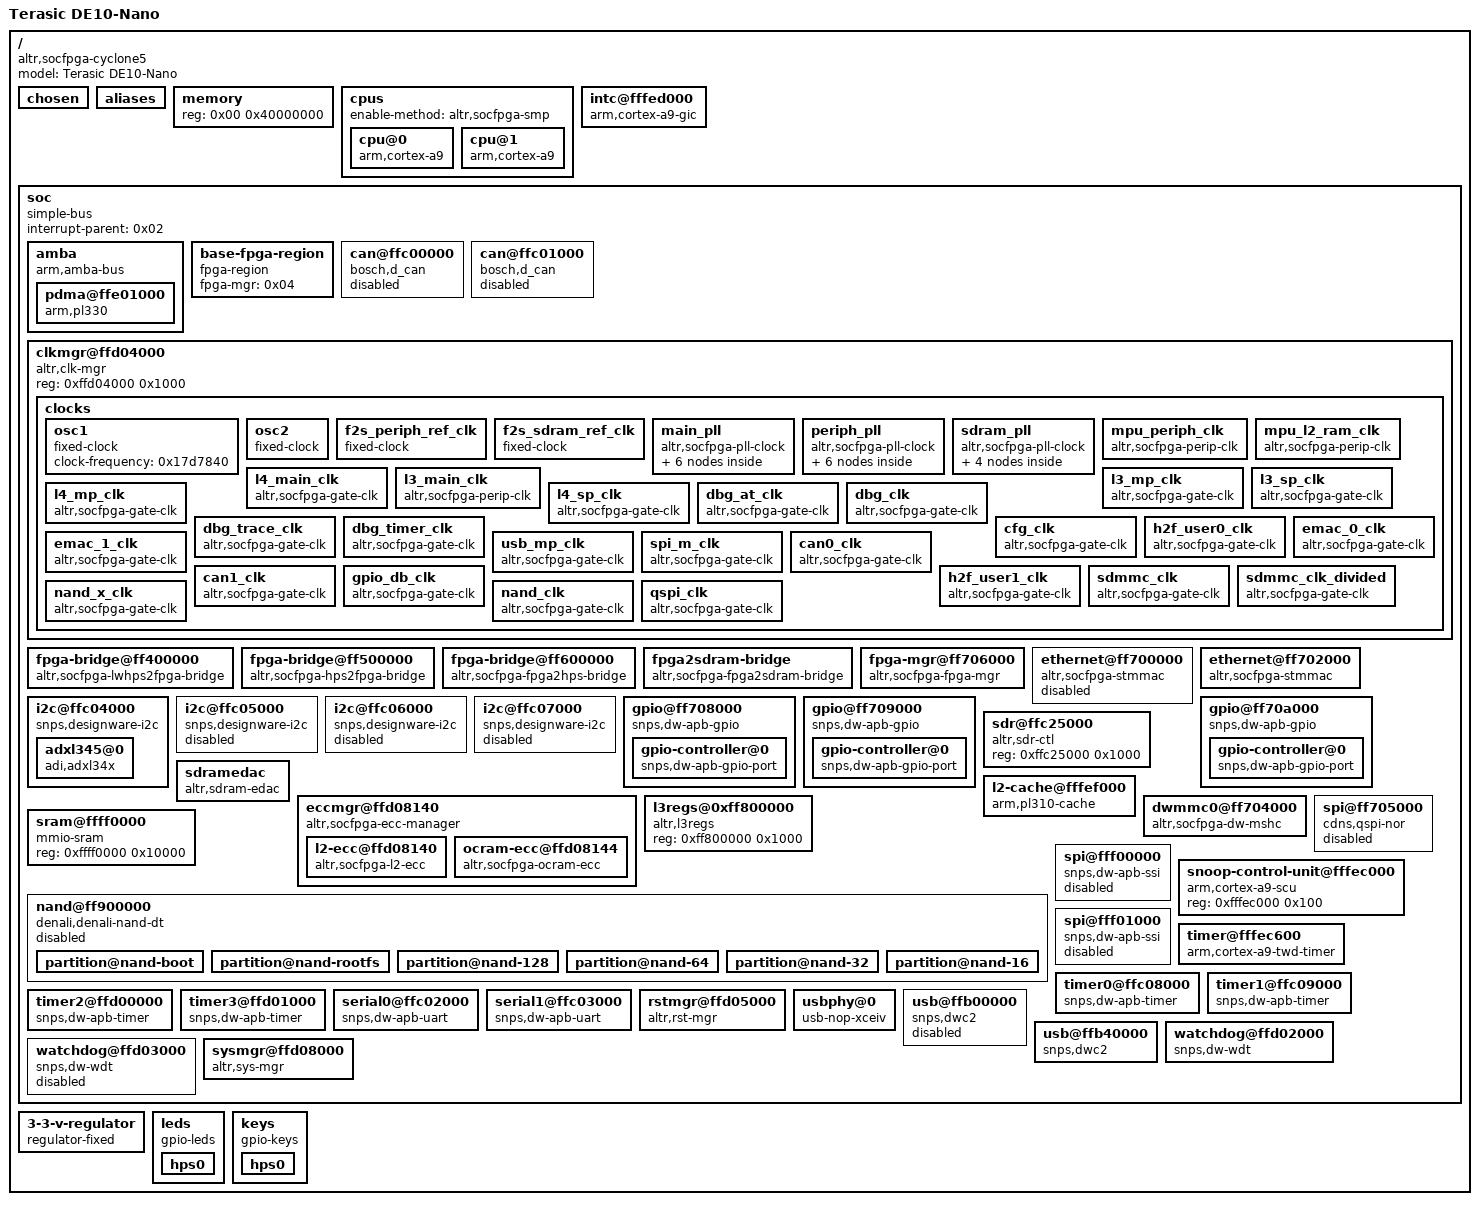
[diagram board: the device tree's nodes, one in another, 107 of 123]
/dts-v1/;

/memreserve/	0x0000000000000000 0x0000000000001000;
/ {
	#address-cells = <0x01>;
	#size-cells = <0x01>;
	model = "Terasic DE10-Nano";
	compatible = "altr,socfpga-cyclone5\0altr,socfpga";

	chosen {
		bootargs = "earlyprintk";
		stdout-path = "serial0:115200n8";
	};

	aliases {
		ethernet0 = "/soc/ethernet@ff702000";
		ethernet1 = "/soc/ethernet@ff702000";
		serial0 = "/soc/serial0@ffc02000";
		serial1 = "/soc/serial1@ffc03000";
		timer0 = "/soc/timer0@ffc08000";
		timer1 = "/soc/timer1@ffc09000";
		timer2 = "/soc/timer2@ffd00000";
		timer3 = "/soc/timer3@ffd01000";
	};

	memory {
		device_type = "memory";
		reg = <0x00 0x40000000>;
	};

	cpus {
		#address-cells = <0x01>;
		#size-cells = <0x00>;
		enable-method = "altr,socfpga-smp";

		cpu@0 {
			compatible = "arm,cortex-a9";
			device_type = "cpu";
			reg = <0x00>;
			next-level-cache = <0x01>;
		};

		cpu@1 {
			compatible = "arm,cortex-a9";
			device_type = "cpu";
			reg = <0x01>;
			next-level-cache = <0x01>;
		};
	};

	intc@fffed000 {
		compatible = "arm,cortex-a9-gic";
		#interrupt-cells = <0x03>;
		interrupt-controller;
		reg = <0xfffed000 0x1000 0xfffec100 0x100>;
		linux,phandle = <0x02>;
		phandle = <0x02>;
	};

	soc {
		#address-cells = <0x01>;
		#size-cells = <0x01>;
		compatible = "simple-bus";
		device_type = "soc";
		interrupt-parent = <0x02>;
		ranges;

		amba {
			compatible = "arm,amba-bus";
			#address-cells = <0x01>;
			#size-cells = <0x01>;
			ranges;

			pdma@ffe01000 {
				compatible = "arm,pl330\0arm,primecell";
				reg = <0xffe01000 0x1000>;
				interrupts = <0x00 0x68 0x04 0x00 0x69 0x04 0x00 0x6a 0x04 0x00 0x6b 0x04 0x00 0x6c 0x04 0x00 0x6d 0x04 0x00 0x6e 0x04 0x00 0x6f 0x04>;
				#dma-cells = <0x01>;
				#dma-channels = <0x08>;
				#dma-requests = <0x20>;
				clocks = <0x03>;
				clock-names = "apb_pclk";
				linux,phandle = <0x28>;
				phandle = <0x28>;
			};
		};

		base-fpga-region {
			compatible = "fpga-region";
			fpga-mgr = <0x04>;
			#address-cells = <0x01>;
			#size-cells = <0x01>;
			linux,phandle = <0x2d>;
			phandle = <0x2d>;
		};

		can@ffc00000 {
			compatible = "bosch,d_can";
			reg = <0xffc00000 0x1000>;
			interrupts = <0x00 0x83 0x04 0x00 0x84 0x04 0x00 0x85 0x04 0x00 0x86 0x04>;
			clocks = <0x05>;
			status = "disabled";
			linux,phandle = <0x2e>;
			phandle = <0x2e>;
		};

		can@ffc01000 {
			compatible = "bosch,d_can";
			reg = <0xffc01000 0x1000>;
			interrupts = <0x00 0x87 0x04 0x00 0x88 0x04 0x00 0x89 0x04 0x00 0x8a 0x04>;
			clocks = <0x06>;
			status = "disabled";
			linux,phandle = <0x2f>;
			phandle = <0x2f>;
		};

		clkmgr@ffd04000 {
			compatible = "altr,clk-mgr";
			reg = <0xffd04000 0x1000>;

			clocks {
				#address-cells = <0x01>;
				#size-cells = <0x00>;

				osc1 {
					#clock-cells = <0x00>;
					compatible = "fixed-clock";
					clock-frequency = <0x17d7840>;
					linux,phandle = <0x07>;
					phandle = <0x07>;
				};

				osc2 {
					#clock-cells = <0x00>;
					compatible = "fixed-clock";
					linux,phandle = <0x09>;
					phandle = <0x09>;
				};

				f2s_periph_ref_clk {
					#clock-cells = <0x00>;
					compatible = "fixed-clock";
					linux,phandle = <0x0a>;
					phandle = <0x0a>;
				};

				f2s_sdram_ref_clk {
					#clock-cells = <0x00>;
					compatible = "fixed-clock";
					linux,phandle = <0x0c>;
					phandle = <0x0c>;
				};

				main_pll {
					#address-cells = <0x01>;
					#size-cells = <0x00>;
					#clock-cells = <0x00>;
					compatible = "altr,socfpga-pll-clock";
					clocks = <0x07>;
					reg = <0x40>;
					linux,phandle = <0x08>;
					phandle = <0x08>;

					mpuclk {
						#clock-cells = <0x00>;
						compatible = "altr,socfpga-perip-clk";
						clocks = <0x08>;
						div-reg = <0xe0 0x00 0x09>;
						reg = <0x48>;
						linux,phandle = <0x0e>;
						phandle = <0x0e>;
					};

					mainclk {
						#clock-cells = <0x00>;
						compatible = "altr,socfpga-perip-clk";
						clocks = <0x08>;
						div-reg = <0xe4 0x00 0x09>;
						reg = <0x4c>;
						linux,phandle = <0x0f>;
						phandle = <0x0f>;
					};

					dbg_base_clk {
						#clock-cells = <0x00>;
						compatible = "altr,socfpga-perip-clk";
						clocks = <0x08 0x07>;
						div-reg = <0xe8 0x00 0x09>;
						reg = <0x50>;
						linux,phandle = <0x12>;
						phandle = <0x12>;
					};

					main_qspi_clk {
						#clock-cells = <0x00>;
						compatible = "altr,socfpga-perip-clk";
						clocks = <0x08>;
						reg = <0x54>;
						linux,phandle = <0x1b>;
						phandle = <0x1b>;
					};

					main_nand_sdmmc_clk {
						#clock-cells = <0x00>;
						compatible = "altr,socfpga-perip-clk";
						clocks = <0x08>;
						reg = <0x58>;
						linux,phandle = <0x18>;
						phandle = <0x18>;
					};

					cfg_h2f_usr0_clk {
						#clock-cells = <0x00>;
						compatible = "altr,socfpga-perip-clk";
						clocks = <0x08>;
						reg = <0x5c>;
						linux,phandle = <0x14>;
						phandle = <0x14>;
					};
				};

				periph_pll {
					#address-cells = <0x01>;
					#size-cells = <0x00>;
					#clock-cells = <0x00>;
					compatible = "altr,socfpga-pll-clock";
					clocks = <0x07 0x09 0x0a>;
					reg = <0x80>;
					linux,phandle = <0x0b>;
					phandle = <0x0b>;

					emac0_clk {
						#clock-cells = <0x00>;
						compatible = "altr,socfpga-perip-clk";
						clocks = <0x0b>;
						reg = <0x88>;
						linux,phandle = <0x15>;
						phandle = <0x15>;
					};

					emac1_clk {
						#clock-cells = <0x00>;
						compatible = "altr,socfpga-perip-clk";
						clocks = <0x0b>;
						reg = <0x8c>;
						linux,phandle = <0x16>;
						phandle = <0x16>;
					};

					per_qsi_clk {
						#clock-cells = <0x00>;
						compatible = "altr,socfpga-perip-clk";
						clocks = <0x0b>;
						reg = <0x90>;
						linux,phandle = <0x1c>;
						phandle = <0x1c>;
					};

					per_nand_mmc_clk {
						#clock-cells = <0x00>;
						compatible = "altr,socfpga-perip-clk";
						clocks = <0x0b>;
						reg = <0x94>;
						linux,phandle = <0x19>;
						phandle = <0x19>;
					};

					per_base_clk {
						#clock-cells = <0x00>;
						compatible = "altr,socfpga-perip-clk";
						clocks = <0x0b>;
						reg = <0x98>;
						linux,phandle = <0x11>;
						phandle = <0x11>;
					};

					h2f_usr1_clk {
						#clock-cells = <0x00>;
						compatible = "altr,socfpga-perip-clk";
						clocks = <0x0b>;
						reg = <0x9c>;
						linux,phandle = <0x17>;
						phandle = <0x17>;
					};
				};

				sdram_pll {
					#address-cells = <0x01>;
					#size-cells = <0x00>;
					#clock-cells = <0x00>;
					compatible = "altr,socfpga-pll-clock";
					clocks = <0x07 0x09 0x0c>;
					reg = <0xc0>;
					linux,phandle = <0x0d>;
					phandle = <0x0d>;

					ddr_dqs_clk {
						#clock-cells = <0x00>;
						compatible = "altr,socfpga-perip-clk";
						clocks = <0x0d>;
						reg = <0xc8>;
						linux,phandle = <0x30>;
						phandle = <0x30>;
					};

					ddr_2x_dqs_clk {
						#clock-cells = <0x00>;
						compatible = "altr,socfpga-perip-clk";
						clocks = <0x0d>;
						reg = <0xcc>;
						linux,phandle = <0x31>;
						phandle = <0x31>;
					};

					ddr_dq_clk {
						#clock-cells = <0x00>;
						compatible = "altr,socfpga-perip-clk";
						clocks = <0x0d>;
						reg = <0xd0>;
						linux,phandle = <0x32>;
						phandle = <0x32>;
					};

					h2f_usr2_clk {
						#clock-cells = <0x00>;
						compatible = "altr,socfpga-perip-clk";
						clocks = <0x0d>;
						reg = <0xd4>;
						linux,phandle = <0x33>;
						phandle = <0x33>;
					};
				};

				mpu_periph_clk {
					#clock-cells = <0x00>;
					compatible = "altr,socfpga-perip-clk";
					clocks = <0x0e>;
					fixed-divider = <0x04>;
					linux,phandle = <0x29>;
					phandle = <0x29>;
				};

				mpu_l2_ram_clk {
					#clock-cells = <0x00>;
					compatible = "altr,socfpga-perip-clk";
					clocks = <0x0e>;
					fixed-divider = <0x02>;
					linux,phandle = <0x34>;
					phandle = <0x34>;
				};

				l4_main_clk {
					#clock-cells = <0x00>;
					compatible = "altr,socfpga-gate-clk";
					clocks = <0x0f>;
					clk-gate = <0x60 0x00>;
					linux,phandle = <0x03>;
					phandle = <0x03>;
				};

				l3_main_clk {
					#clock-cells = <0x00>;
					compatible = "altr,socfpga-perip-clk";
					clocks = <0x0f>;
					fixed-divider = <0x01>;
					linux,phandle = <0x35>;
					phandle = <0x35>;
				};

				l3_mp_clk {
					#clock-cells = <0x00>;
					compatible = "altr,socfpga-gate-clk";
					clocks = <0x0f>;
					div-reg = <0x64 0x00 0x02>;
					clk-gate = <0x60 0x01>;
					linux,phandle = <0x10>;
					phandle = <0x10>;
				};

				l3_sp_clk {
					#clock-cells = <0x00>;
					compatible = "altr,socfpga-gate-clk";
					clocks = <0x10>;
					div-reg = <0x64 0x02 0x02>;
					linux,phandle = <0x36>;
					phandle = <0x36>;
				};

				l4_mp_clk {
					#clock-cells = <0x00>;
					compatible = "altr,socfpga-gate-clk";
					clocks = <0x0f 0x11>;
					div-reg = <0x64 0x04 0x03>;
					clk-gate = <0x60 0x02>;
					linux,phandle = <0x21>;
					phandle = <0x21>;
				};

				l4_sp_clk {
					#clock-cells = <0x00>;
					compatible = "altr,socfpga-gate-clk";
					clocks = <0x0f 0x11>;
					div-reg = <0x64 0x07 0x03>;
					clk-gate = <0x60 0x03>;
					linux,phandle = <0x1f>;
					phandle = <0x1f>;
				};

				dbg_at_clk {
					#clock-cells = <0x00>;
					compatible = "altr,socfpga-gate-clk";
					clocks = <0x12>;
					div-reg = <0x68 0x00 0x02>;
					clk-gate = <0x60 0x04>;
					linux,phandle = <0x13>;
					phandle = <0x13>;
				};

				dbg_clk {
					#clock-cells = <0x00>;
					compatible = "altr,socfpga-gate-clk";
					clocks = <0x13>;
					div-reg = <0x68 0x02 0x02>;
					clk-gate = <0x60 0x05>;
					linux,phandle = <0x37>;
					phandle = <0x37>;
				};

				dbg_trace_clk {
					#clock-cells = <0x00>;
					compatible = "altr,socfpga-gate-clk";
					clocks = <0x12>;
					div-reg = <0x6c 0x00 0x03>;
					clk-gate = <0x60 0x06>;
					linux,phandle = <0x38>;
					phandle = <0x38>;
				};

				dbg_timer_clk {
					#clock-cells = <0x00>;
					compatible = "altr,socfpga-gate-clk";
					clocks = <0x12>;
					clk-gate = <0x60 0x07>;
					linux,phandle = <0x39>;
					phandle = <0x39>;
				};

				cfg_clk {
					#clock-cells = <0x00>;
					compatible = "altr,socfpga-gate-clk";
					clocks = <0x14>;
					clk-gate = <0x60 0x08>;
					linux,phandle = <0x3a>;
					phandle = <0x3a>;
				};

				h2f_user0_clk {
					#clock-cells = <0x00>;
					compatible = "altr,socfpga-gate-clk";
					clocks = <0x14>;
					clk-gate = <0x60 0x09>;
					linux,phandle = <0x3b>;
					phandle = <0x3b>;
				};

				emac_0_clk {
					#clock-cells = <0x00>;
					compatible = "altr,socfpga-gate-clk";
					clocks = <0x15>;
					clk-gate = <0xa0 0x00>;
					linux,phandle = <0x3c>;
					phandle = <0x3c>;
				};

				emac_1_clk {
					#clock-cells = <0x00>;
					compatible = "altr,socfpga-gate-clk";
					clocks = <0x16>;
					clk-gate = <0xa0 0x01>;
					linux,phandle = <0x3d>;
					phandle = <0x3d>;
				};

				usb_mp_clk {
					#clock-cells = <0x00>;
					compatible = "altr,socfpga-gate-clk";
					clocks = <0x11>;
					clk-gate = <0xa0 0x02>;
					div-reg = <0xa4 0x00 0x03>;
					linux,phandle = <0x2a>;
					phandle = <0x2a>;
				};

				spi_m_clk {
					#clock-cells = <0x00>;
					compatible = "altr,socfpga-gate-clk";
					clocks = <0x11>;
					clk-gate = <0xa0 0x03>;
					div-reg = <0xa4 0x03 0x03>;
					linux,phandle = <0x3e>;
					phandle = <0x3e>;
				};

				can0_clk {
					#clock-cells = <0x00>;
					compatible = "altr,socfpga-gate-clk";
					clocks = <0x11>;
					clk-gate = <0xa0 0x04>;
					div-reg = <0xa4 0x06 0x03>;
					linux,phandle = <0x05>;
					phandle = <0x05>;
				};

				can1_clk {
					#clock-cells = <0x00>;
					compatible = "altr,socfpga-gate-clk";
					clocks = <0x11>;
					clk-gate = <0xa0 0x05>;
					div-reg = <0xa4 0x09 0x03>;
					linux,phandle = <0x06>;
					phandle = <0x06>;
				};

				gpio_db_clk {
					#clock-cells = <0x00>;
					compatible = "altr,socfpga-gate-clk";
					clocks = <0x11>;
					clk-gate = <0xa0 0x06>;
					div-reg = <0xa8 0x00 0x18>;
					linux,phandle = <0x3f>;
					phandle = <0x3f>;
				};

				h2f_user1_clk {
					#clock-cells = <0x00>;
					compatible = "altr,socfpga-gate-clk";
					clocks = <0x17>;
					clk-gate = <0xa0 0x07>;
					linux,phandle = <0x40>;
					phandle = <0x40>;
				};

				sdmmc_clk {
					#clock-cells = <0x00>;
					compatible = "altr,socfpga-gate-clk";
					clocks = <0x0a 0x18 0x19>;
					clk-gate = <0xa0 0x08>;
					clk-phase = <0x00 0x87>;
					linux,phandle = <0x1a>;
					phandle = <0x1a>;
				};

				sdmmc_clk_divided {
					#clock-cells = <0x00>;
					compatible = "altr,socfpga-gate-clk";
					clocks = <0x1a>;
					clk-gate = <0xa0 0x08>;
					fixed-divider = <0x04>;
					linux,phandle = <0x24>;
					phandle = <0x24>;
				};

				nand_x_clk {
					#clock-cells = <0x00>;
					compatible = "altr,socfpga-gate-clk";
					clocks = <0x0a 0x18 0x19>;
					clk-gate = <0xa0 0x09>;
					linux,phandle = <0x41>;
					phandle = <0x41>;
				};

				nand_clk {
					#clock-cells = <0x00>;
					compatible = "altr,socfpga-gate-clk";
					clocks = <0x0a 0x18 0x19>;
					clk-gate = <0xa0 0x0a>;
					fixed-divider = <0x04>;
					linux,phandle = <0x26>;
					phandle = <0x26>;
				};

				qspi_clk {
					#clock-cells = <0x00>;
					compatible = "altr,socfpga-gate-clk";
					clocks = <0x0a 0x1b 0x1c>;
					clk-gate = <0xa0 0x0b>;
					linux,phandle = <0x27>;
					phandle = <0x27>;
				};
			};
		};

		fpga-bridge@ff400000 {
			compatible = "altr,socfpga-lwhps2fpga-bridge";
			reg = <0xff400000 0x100000>;
			resets = <0x1d 0x61>;
			reset-names = "lwhps2fpga";
			clocks = <0x03>;
			linux,phandle = <0x42>;
			phandle = <0x42>;
		};

		fpga-bridge@ff500000 {
			compatible = "altr,socfpga-hps2fpga-bridge";
			reg = <0xff500000 0x10000>;
			resets = <0x1d 0x60>;
			reset-names = "hps2fpga";
			clocks = <0x03>;
			linux,phandle = <0x43>;
			phandle = <0x43>;
		};

		fpga-bridge@ff600000 {
			compatible = "altr,socfpga-fpga2hps-bridge";
			reg = <0xff600000 0x100000>;
			resets = <0x1d 0x62>;
			reset-names = "fpga2hps";
			clocks = <0x03>;
			linux,phandle = <0x44>;
			phandle = <0x44>;
		};

		fpga2sdram-bridge {
			compatible = "altr,socfpga-fpga2sdram-bridge";
			linux,phandle = <0x45>;
			phandle = <0x45>;
		};

		fpga-mgr@ff706000 {
			compatible = "altr,socfpga-fpga-mgr";
			reg = <0xff706000 0x1000 0xffb90000 0x20>;
			interrupts = <0x00 0xaf 0x04>;
			linux,phandle = <0x04>;
			phandle = <0x04>;
		};

		ethernet@ff700000 {
			compatible = "altr,socfpga-stmmac\0snps,dwmac-3.70a\0snps,dwmac";
			altr,sysmgr-syscon = <0x1e 0x60 0x00>;
			reg = <0xff700000 0x2000>;
			interrupts = <0x00 0x73 0x04>;
			interrupt-names = "macirq";
			mac-address = [00 00 00 00 00 00];
			clocks = <0x15>;
			clock-names = "stmmaceth";
			resets = <0x1d 0x20>;
			reset-names = "stmmaceth";
			snps,multicast-filter-bins = <0x100>;
			snps,perfect-filter-entries = <0x80>;
			tx-fifo-depth = <0x1000>;
			rx-fifo-depth = <0x1000>;
			status = "disabled";
			linux,phandle = <0x46>;
			phandle = <0x46>;
		};

		ethernet@ff702000 {
			compatible = "altr,socfpga-stmmac\0snps,dwmac-3.70a\0snps,dwmac";
			altr,sysmgr-syscon = <0x1e 0x60 0x02>;
			reg = <0xff702000 0x2000>;
			interrupts = <0x00 0x78 0x04>;
			interrupt-names = "macirq";
			mac-address = [00 00 00 00 00 00];
			clocks = <0x16>;
			clock-names = "stmmaceth";
			resets = <0x1d 0x21>;
			reset-names = "stmmaceth";
			snps,multicast-filter-bins = <0x100>;
			snps,perfect-filter-entries = <0x80>;
			tx-fifo-depth = <0x1000>;
			rx-fifo-depth = <0x1000>;
			status = "okay";
			phy-mode = "rgmii";
			phy-addr = <0xffffffff>;
			txd0-skew-ps = <0x00>;
			txd1-skew-ps = <0x00>;
			txd2-skew-ps = <0x00>;
			txd3-skew-ps = <0x00>;
			rxd0-skew-ps = <0x1a4>;
			rxd1-skew-ps = <0x1a4>;
			rxd2-skew-ps = <0x1a4>;
			rxd3-skew-ps = <0x1a4>;
			txen-skew-ps = <0x00>;
			txc-skew-ps = <0x744>;
			rxdv-skew-ps = <0x1a4>;
			rxc-skew-ps = <0x690>;
			max-frame-size = <0xed8>;
			linux,phandle = <0x47>;
			phandle = <0x47>;
		};

		i2c@ffc04000 {
			#address-cells = <0x01>;
			#size-cells = <0x00>;
			compatible = "snps,designware-i2c";
			reg = <0xffc04000 0x1000>;
			clocks = <0x1f>;
			interrupts = <0x00 0x9e 0x04>;
			status = "okay";
			speed-mode = <0x00>;
			linux,phandle = <0x48>;
			phandle = <0x48>;

			adxl345@0 {
				compatible = "adi,adxl34x";
				reg = <0x53>;
				interrupt-parent = <0x20>;
				interrupts = <0x03 0x02>;
				linux,phandle = <0x49>;
				phandle = <0x49>;
			};
		};

		i2c@ffc05000 {
			#address-cells = <0x01>;
			#size-cells = <0x00>;
			compatible = "snps,designware-i2c";
			reg = <0xffc05000 0x1000>;
			clocks = <0x1f>;
			interrupts = <0x00 0x9f 0x04>;
			status = "disabled";
			linux,phandle = <0x4a>;
			phandle = <0x4a>;
		};

		i2c@ffc06000 {
			#address-cells = <0x01>;
			#size-cells = <0x00>;
			compatible = "snps,designware-i2c";
			reg = <0xffc06000 0x1000>;
			clocks = <0x1f>;
			interrupts = <0x00 0xa0 0x04>;
			status = "disabled";
			linux,phandle = <0x4b>;
			phandle = <0x4b>;
		};

		i2c@ffc07000 {
			#address-cells = <0x01>;
			#size-cells = <0x00>;
			compatible = "snps,designware-i2c";
			reg = <0xffc07000 0x1000>;
			clocks = <0x1f>;
			interrupts = <0x00 0xa1 0x04>;
			status = "disabled";
			linux,phandle = <0x4c>;
			phandle = <0x4c>;
		};

		gpio@ff708000 {
			#address-cells = <0x01>;
			#size-cells = <0x00>;
			compatible = "snps,dw-apb-gpio";
			reg = <0xff708000 0x1000>;
			clocks = <0x21>;
			status = "okay";
			linux,phandle = <0x4d>;
			phandle = <0x4d>;

			gpio-controller@0 {
				compatible = "snps,dw-apb-gpio-port";
				gpio-controller;
				#gpio-cells = <0x02>;
				snps,nr-gpios = <0x1d>;
				reg = <0x00>;
				interrupt-controller;
				#interrupt-cells = <0x02>;
				interrupts = <0x00 0xa4 0x04>;
				linux,phandle = <0x4e>;
				phandle = <0x4e>;
			};
		};

		gpio@ff709000 {
			#address-cells = <0x01>;
			#size-cells = <0x00>;
			compatible = "snps,dw-apb-gpio";
			reg = <0xff709000 0x1000>;
			clocks = <0x21>;
			status = "okay";
			linux,phandle = <0x4f>;
			phandle = <0x4f>;

			gpio-controller@0 {
				compatible = "snps,dw-apb-gpio-port";
				gpio-controller;
				#gpio-cells = <0x02>;
				snps,nr-gpios = <0x1d>;
				reg = <0x00>;
				interrupt-controller;
				#interrupt-cells = <0x02>;
				interrupts = <0x00 0xa5 0x04>;
				linux,phandle = <0x2c>;
				phandle = <0x2c>;
			};
		};

		gpio@ff70a000 {
			#address-cells = <0x01>;
			#size-cells = <0x00>;
			compatible = "snps,dw-apb-gpio";
			reg = <0xff70a000 0x1000>;
			clocks = <0x21>;
			status = "okay";
			linux,phandle = <0x50>;
			phandle = <0x50>;

			gpio-controller@0 {
				compatible = "snps,dw-apb-gpio-port";
				gpio-controller;
				#gpio-cells = <0x02>;
				snps,nr-gpios = <0x1b>;
				reg = <0x00>;
				interrupt-controller;
				#interrupt-cells = <0x02>;
				interrupts = <0x00 0xa6 0x04>;
				linux,phandle = <0x20>;
				phandle = <0x20>;
			};
		};

		sdr@ffc25000 {
			compatible = "altr,sdr-ctl\0syscon";
			reg = <0xffc25000 0x1000>;
			linux,phandle = <0x22>;
			phandle = <0x22>;
		};

		sdramedac {
			compatible = "altr,sdram-edac";
			altr,sdr-syscon = <0x22>;
			interrupts = <0x00 0x27 0x04>;
		};

		eccmgr@ffd08140 {
			compatible = "altr,socfpga-ecc-manager";
			#address-cells = <0x01>;
			#size-cells = <0x01>;
			ranges;
			linux,phandle = <0x51>;
			phandle = <0x51>;

			l2-ecc@ffd08140 {
				compatible = "altr,socfpga-l2-ecc";
				reg = <0xffd08140 0x04>;
				interrupts = <0x00 0x24 0x01 0x00 0x25 0x01>;
			};

			ocram-ecc@ffd08144 {
				compatible = "altr,socfpga-ocram-ecc";
				reg = <0xffd08144 0x04>;
				iram = <0x23>;
				interrupts = <0x00 0xb2 0x01 0x00 0xb3 0x01>;
			};
		};

		l2-cache@fffef000 {
			compatible = "arm,pl310-cache";
			reg = <0xfffef000 0x1000>;
			interrupts = <0x00 0x26 0x04>;
			cache-unified;
			cache-level = <0x02>;
			arm,tag-latency = <0x01 0x01 0x01>;
			arm,data-latency = <0x02 0x01 0x01>;
			prefetch-data = <0x01>;
			prefetch-instr = <0x01>;
			linux,phandle = <0x01>;
			phandle = <0x01>;
		};

		l3regs@0xff800000 {
			compatible = "altr,l3regs\0syscon";
			reg = <0xff800000 0x1000>;
		};

		dwmmc0@ff704000 {
			compatible = "altr,socfpga-dw-mshc";
			reg = <0xff704000 0x1000>;
			interrupts = <0x00 0x8b 0x04>;
			fifo-depth = <0x400>;
			#address-cells = <0x01>;
			#size-cells = <0x00>;
			clocks = <0x21 0x24>;
			clock-names = "biu\0ciu";
			num-slots = <0x01>;
			broken-cd;
			bus-width = <0x04>;
			cap-mmc-highspeed;
			cap-sd-highspeed;
			vmmc-supply = <0x25>;
			vqmmc-supply = <0x25>;
			linux,phandle = <0x52>;
			phandle = <0x52>;
		};

		sram@ffff0000 {
			compatible = "mmio-sram";
			reg = <0xffff0000 0x10000>;
			linux,phandle = <0x23>;
			phandle = <0x23>;
		};

		nand@ff900000 {
			#address-cells = <0x01>;
			#size-cells = <0x01>;
			compatible = "denali,denali-nand-dt";
			reg = <0xff900000 0x100000 0xffb80000 0x10000>;
			reg-names = "nand_data\0denali_reg";
			interrupts = <0x00 0x90 0x04>;
			dma-mask = <0xffffffff>;
			clocks = <0x26>;
			have-hw-ecc-fixup;
			status = "disabled";
			linux,phandle = <0x53>;
			phandle = <0x53>;

			partition@nand-boot {
				label = "NAND Flash Boot Area 8MB";
				reg = <0x00 0x800000>;
			};

			partition@nand-rootfs {
				label = "NAND Flash jffs2 Root Filesystem 128MB";
				reg = <0x800000 0x8000000>;
			};

			partition@nand-128 {
				label = "NAND Flash 128 MB";
				reg = <0x8800000 0x8000000>;
			};

			partition@nand-64 {
				label = "NAND Flash 64 MB";
				reg = <0x10800000 0x4000000>;
			};

			partition@nand-32 {
				label = "NAND Flash 32 MB";
				reg = <0x14800000 0x2000000>;
			};

			partition@nand-16 {
				label = "NAND Flash 16 MB";
				reg = <0x16800000 0x1000000>;
			};
		};

		spi@ff705000 {
			compatible = "cdns,qspi-nor";
			#address-cells = <0x01>;
			#size-cells = <0x00>;
			reg = <0xff705000 0x1000 0xffa00000 0x1000>;
			interrupts = <0x00 0x97 0x04>;
			clocks = <0x27>;
			is-decoded-cs = <0x01>;
			fifo-depth = <0x80>;
			status = "disabled";
			m25p,fast-read;
			linux,phandle = <0x54>;
			phandle = <0x54>;
		};

		spi@fff00000 {
			compatible = "snps,dw-apb-ssi";
			#address-cells = <0x01>;
			#size-cells = <0x00>;
			reg = <0xfff00000 0x1000>;
			interrupts = <0x00 0x9a 0x04>;
			num-cs = <0x04>;
			tx-dma-channel = <0x28 0x10>;
			rx-dma-channel = <0x28 0x11>;
			clocks = <0x11>;
			status = "disabled";
			linux,phandle = <0x55>;
			phandle = <0x55>;
		};

		snoop-control-unit@fffec000 {
			compatible = "arm,cortex-a9-scu";
			reg = <0xfffec000 0x100>;
			linux,phandle = <0x56>;
			phandle = <0x56>;
		};

		spi@fff01000 {
			compatible = "snps,dw-apb-ssi";
			#address-cells = <0x01>;
			#size-cells = <0x00>;
			reg = <0xfff01000 0x1000>;
			interrupts = <0x00 0x9b 0x04>;
			num-cs = <0x04>;
			tx-dma-channel = <0x28 0x14>;
			rx-dma-channel = <0x28 0x15>;
			clocks = <0x11>;
			status = "disabled";
			linux,phandle = <0x57>;
			phandle = <0x57>;
		};

		timer@fffec600 {
			compatible = "arm,cortex-a9-twd-timer";
			reg = <0xfffec600 0x100>;
			interrupts = <0x01 0x0d 0xf04>;
			clocks = <0x29>;
		};

		timer0@ffc08000 {
			compatible = "snps,dw-apb-timer";
			interrupts = <0x00 0xa7 0x04>;
			reg = <0xffc08000 0x1000>;
			clocks = <0x1f>;
			clock-names = "timer";
			linux,phandle = <0x58>;
			phandle = <0x58>;
		};

		timer1@ffc09000 {
			compatible = "snps,dw-apb-timer";
			interrupts = <0x00 0xa8 0x04>;
			reg = <0xffc09000 0x1000>;
			clocks = <0x1f>;
			clock-names = "timer";
			linux,phandle = <0x59>;
			phandle = <0x59>;
		};

		timer2@ffd00000 {
			compatible = "snps,dw-apb-timer";
			interrupts = <0x00 0xa9 0x04>;
			reg = <0xffd00000 0x1000>;
			clocks = <0x07>;
			clock-names = "timer";
			linux,phandle = <0x5a>;
			phandle = <0x5a>;
		};

		timer3@ffd01000 {
			compatible = "snps,dw-apb-timer";
			interrupts = <0x00 0xaa 0x04>;
			reg = <0xffd01000 0x1000>;
			clocks = <0x07>;
			clock-names = "timer";
			linux,phandle = <0x5b>;
			phandle = <0x5b>;
		};

		serial0@ffc02000 {
			compatible = "snps,dw-apb-uart";
			reg = <0xffc02000 0x1000>;
			interrupts = <0x00 0xa2 0x04>;
			reg-shift = <0x02>;
			reg-io-width = <0x04>;
			clocks = <0x1f>;
			dmas = <0x28 0x1c 0x28 0x1d>;
			dma-names = "tx\0rx";
			status = "okay";
			linux,phandle = <0x5c>;
			phandle = <0x5c>;
		};

		serial1@ffc03000 {
			compatible = "snps,dw-apb-uart";
			reg = <0xffc03000 0x1000>;
			interrupts = <0x00 0xa3 0x04>;
			reg-shift = <0x02>;
			reg-io-width = <0x04>;
			clocks = <0x1f>;
			dmas = <0x28 0x1e 0x28 0x1f>;
			dma-names = "tx\0rx";
			linux,phandle = <0x5d>;
			phandle = <0x5d>;
		};

		rstmgr@ffd05000 {
			#reset-cells = <0x01>;
			compatible = "altr,rst-mgr";
			reg = <0xffd05000 0x1000>;
			altr,modrst-offset = <0x10>;
			linux,phandle = <0x1d>;
			phandle = <0x1d>;
		};

		usbphy@0 {
			#phy-cells = <0x00>;
			compatible = "usb-nop-xceiv";
			status = "okay";
			linux,phandle = <0x2b>;
			phandle = <0x2b>;
		};

		usb@ffb00000 {
			compatible = "snps,dwc2";
			reg = <0xffb00000 0xffff>;
			interrupts = <0x00 0x7d 0x04>;
			clocks = <0x2a>;
			clock-names = "otg";
			phys = <0x2b>;
			phy-names = "usb2-phy";
			status = "disabled";
			linux,phandle = <0x5e>;
			phandle = <0x5e>;
		};

		usb@ffb40000 {
			compatible = "snps,dwc2";
			reg = <0xffb40000 0xffff>;
			interrupts = <0x00 0x80 0x04>;
			clocks = <0x2a>;
			clock-names = "otg";
			phys = <0x2b>;
			phy-names = "usb2-phy";
			status = "okay";
			linux,phandle = <0x5f>;
			phandle = <0x5f>;
		};

		watchdog@ffd02000 {
			compatible = "snps,dw-wdt";
			reg = <0xffd02000 0x1000>;
			interrupts = <0x00 0xab 0x04>;
			clocks = <0x07>;
			status = "okay";
			linux,phandle = <0x60>;
			phandle = <0x60>;
		};

		watchdog@ffd03000 {
			compatible = "snps,dw-wdt";
			reg = <0xffd03000 0x1000>;
			interrupts = <0x00 0xac 0x04>;
			clocks = <0x07>;
			status = "disabled";
			linux,phandle = <0x61>;
			phandle = <0x61>;
		};

		sysmgr@ffd08000 {
			compatible = "altr,sys-mgr\0syscon";
			reg = <0xffd08000 0x4000>;
			cpu1-start-addr = <0xffd080c4>;
			linux,phandle = <0x1e>;
			phandle = <0x1e>;
		};
	};

	3-3-v-regulator {
		compatible = "regulator-fixed";
		regulator-name = "3.3V";
		regulator-min-microvolt = <0x325aa0>;
		regulator-max-microvolt = <0x325aa0>;
		linux,phandle = <0x25>;
		phandle = <0x25>;
	};

	leds {
		compatible = "gpio-leds";

		hps0 {
			label = "hps_led0";
			gpios = <0x2c 0x18 0x00>;
			linux,default-trigger = "heartbeat";
		};
	};

	keys {
		compatible = "gpio-keys";

		hps0 {
			label = "hps_key0";
			gpios = <0x2c 0x19 0x00>;
			linux,code = <0x3f>;
			debounce-interval = <0x32>;
		};
	};

	__symbols__ {
		intc = "/intc@fffed000";
		pdma = "/soc/amba/pdma@ffe01000";
		base_fpga_region = "/soc/base-fpga-region";
		can0 = "/soc/can@ffc00000";
		can1 = "/soc/can@ffc01000";
		osc1 = "/soc/clkmgr@ffd04000/clocks/osc1";
		osc2 = "/soc/clkmgr@ffd04000/clocks/osc2";
		f2s_periph_ref_clk = "/soc/clkmgr@ffd04000/clocks/f2s_periph_ref_clk";
		f2s_sdram_ref_clk = "/soc/clkmgr@ffd04000/clocks/f2s_sdram_ref_clk";
		main_pll = "/soc/clkmgr@ffd04000/clocks/main_pll";
		mpuclk = "/soc/clkmgr@ffd04000/clocks/main_pll/mpuclk";
		mainclk = "/soc/clkmgr@ffd04000/clocks/main_pll/mainclk";
		dbg_base_clk = "/soc/clkmgr@ffd04000/clocks/main_pll/dbg_base_clk";
		main_qspi_clk = "/soc/clkmgr@ffd04000/clocks/main_pll/main_qspi_clk";
		main_nand_sdmmc_clk = "/soc/clkmgr@ffd04000/clocks/main_pll/main_nand_sdmmc_clk";
		cfg_h2f_usr0_clk = "/soc/clkmgr@ffd04000/clocks/main_pll/cfg_h2f_usr0_clk";
		periph_pll = "/soc/clkmgr@ffd04000/clocks/periph_pll";
		emac0_clk = "/soc/clkmgr@ffd04000/clocks/periph_pll/emac0_clk";
		emac1_clk = "/soc/clkmgr@ffd04000/clocks/periph_pll/emac1_clk";
		per_qspi_clk = "/soc/clkmgr@ffd04000/clocks/periph_pll/per_qsi_clk";
		per_nand_mmc_clk = "/soc/clkmgr@ffd04000/clocks/periph_pll/per_nand_mmc_clk";
		per_base_clk = "/soc/clkmgr@ffd04000/clocks/periph_pll/per_base_clk";
		h2f_usr1_clk = "/soc/clkmgr@ffd04000/clocks/periph_pll/h2f_usr1_clk";
		sdram_pll = "/soc/clkmgr@ffd04000/clocks/sdram_pll";
		ddr_dqs_clk = "/soc/clkmgr@ffd04000/clocks/sdram_pll/ddr_dqs_clk";
		ddr_2x_dqs_clk = "/soc/clkmgr@ffd04000/clocks/sdram_pll/ddr_2x_dqs_clk";
		ddr_dq_clk = "/soc/clkmgr@ffd04000/clocks/sdram_pll/ddr_dq_clk";
		h2f_usr2_clk = "/soc/clkmgr@ffd04000/clocks/sdram_pll/h2f_usr2_clk";
		mpu_periph_clk = "/soc/clkmgr@ffd04000/clocks/mpu_periph_clk";
		mpu_l2_ram_clk = "/soc/clkmgr@ffd04000/clocks/mpu_l2_ram_clk";
		l4_main_clk = "/soc/clkmgr@ffd04000/clocks/l4_main_clk";
		l3_main_clk = "/soc/clkmgr@ffd04000/clocks/l3_main_clk";
		l3_mp_clk = "/soc/clkmgr@ffd04000/clocks/l3_mp_clk";
		l3_sp_clk = "/soc/clkmgr@ffd04000/clocks/l3_sp_clk";
		l4_mp_clk = "/soc/clkmgr@ffd04000/clocks/l4_mp_clk";
		l4_sp_clk = "/soc/clkmgr@ffd04000/clocks/l4_sp_clk";
		dbg_at_clk = "/soc/clkmgr@ffd04000/clocks/dbg_at_clk";
		dbg_clk = "/soc/clkmgr@ffd04000/clocks/dbg_clk";
		dbg_trace_clk = "/soc/clkmgr@ffd04000/clocks/dbg_trace_clk";
		dbg_timer_clk = "/soc/clkmgr@ffd04000/clocks/dbg_timer_clk";
		cfg_clk = "/soc/clkmgr@ffd04000/clocks/cfg_clk";
		h2f_user0_clk = "/soc/clkmgr@ffd04000/clocks/h2f_user0_clk";
		emac_0_clk = "/soc/clkmgr@ffd04000/clocks/emac_0_clk";
		emac_1_clk = "/soc/clkmgr@ffd04000/clocks/emac_1_clk";
		usb_mp_clk = "/soc/clkmgr@ffd04000/clocks/usb_mp_clk";
		spi_m_clk = "/soc/clkmgr@ffd04000/clocks/spi_m_clk";
		can0_clk = "/soc/clkmgr@ffd04000/clocks/can0_clk";
		can1_clk = "/soc/clkmgr@ffd04000/clocks/can1_clk";
		gpio_db_clk = "/soc/clkmgr@ffd04000/clocks/gpio_db_clk";
		h2f_user1_clk = "/soc/clkmgr@ffd04000/clocks/h2f_user1_clk";
		sdmmc_clk = "/soc/clkmgr@ffd04000/clocks/sdmmc_clk";
		sdmmc_clk_divided = "/soc/clkmgr@ffd04000/clocks/sdmmc_clk_divided";
		nand_x_clk = "/soc/clkmgr@ffd04000/clocks/nand_x_clk";
		nand_clk = "/soc/clkmgr@ffd04000/clocks/nand_clk";
		qspi_clk = "/soc/clkmgr@ffd04000/clocks/qspi_clk";
		fpga_bridge0 = "/soc/fpga-bridge@ff400000";
		fpga_bridge1 = "/soc/fpga-bridge@ff500000";
		fpga_bridge2 = "/soc/fpga-bridge@ff600000";
		fpga_bridge3 = "/soc/fpga2sdram-bridge";
		fpga_mgr = "/soc/fpga-mgr@ff706000";
		gmac0 = "/soc/ethernet@ff700000";
		gmac1 = "/soc/ethernet@ff702000";
		i2c0 = "/soc/i2c@ffc04000";
		adxl345 = "/soc/i2c@ffc04000/adxl345@0";
		i2c1 = "/soc/i2c@ffc05000";
		i2c2 = "/soc/i2c@ffc06000";
		i2c3 = "/soc/i2c@ffc07000";
		gpio0 = "/soc/gpio@ff708000";
		porta = "/soc/gpio@ff708000/gpio-controller@0";
		gpio1 = "/soc/gpio@ff709000";
		portb = "/soc/gpio@ff709000/gpio-controller@0";
		gpio2 = "/soc/gpio@ff70a000";
		portc = "/soc/gpio@ff70a000/gpio-controller@0";
		sdr = "/soc/sdr@ffc25000";
		eccmgr = "/soc/eccmgr@ffd08140";
		L2 = "/soc/l2-cache@fffef000";
		mmc0 = "/soc/dwmmc0@ff704000";
		mmc = "/soc/dwmmc0@ff704000";
		ocram = "/soc/sram@ffff0000";
		nand = "/soc/nand@ff900000";
		qspi = "/soc/spi@ff705000";
		spi0 = "/soc/spi@fff00000";
		scu = "/soc/snoop-control-unit@fffec000";
		spi1 = "/soc/spi@fff01000";
		timer0 = "/soc/timer0@ffc08000";
		timer1 = "/soc/timer1@ffc09000";
		timer2 = "/soc/timer2@ffd00000";
		timer3 = "/soc/timer3@ffd01000";
		uart0 = "/soc/serial0@ffc02000";
		uart1 = "/soc/serial1@ffc03000";
		rst = "/soc/rstmgr@ffd05000";
		usbphy0 = "/soc/usbphy@0";
		usb0 = "/soc/usb@ffb00000";
		usb1 = "/soc/usb@ffb40000";
		watchdog0 = "/soc/watchdog@ffd02000";
		watchdog1 = "/soc/watchdog@ffd03000";
		sysmgr = "/soc/sysmgr@ffd08000";
		regulator_3_3v = "/3-3-v-regulator";
	};

	__local_fixups__ {

		cpus {

			cpu@0 {
				next-level-cache = <0x00>;
			};

			cpu@1 {
				next-level-cache = <0x00>;
			};
		};

		soc {
			interrupt-parent = <0x00>;

			amba {

				pdma@ffe01000 {
					clocks = <0x00>;
				};
			};

			base-fpga-region {
				fpga-mgr = <0x00>;
			};

			can@ffc00000 {
				clocks = <0x00>;
			};

			can@ffc01000 {
				clocks = <0x00>;
			};

			clkmgr@ffd04000 {

				clocks {

					main_pll {
						clocks = <0x00>;

						mpuclk {
							clocks = <0x00>;
						};

						mainclk {
							clocks = <0x00>;
						};

						dbg_base_clk {
							clocks = <0x00 0x04>;
						};

						main_qspi_clk {
							clocks = <0x00>;
						};

						main_nand_sdmmc_clk {
							clocks = <0x00>;
						};

						cfg_h2f_usr0_clk {
							clocks = <0x00>;
						};
					};

					periph_pll {
						clocks = <0x00 0x04 0x08>;

						emac0_clk {
							clocks = <0x00>;
						};

						emac1_clk {
							clocks = <0x00>;
						};

						per_qsi_clk {
							clocks = <0x00>;
						};

						per_nand_mmc_clk {
							clocks = <0x00>;
						};

						per_base_clk {
							clocks = <0x00>;
						};

						h2f_usr1_clk {
							clocks = <0x00>;
						};
					};

					sdram_pll {
						clocks = <0x00 0x04 0x08>;

						ddr_dqs_clk {
							clocks = <0x00>;
						};

						ddr_2x_dqs_clk {
							clocks = <0x00>;
						};

						ddr_dq_clk {
							clocks = <0x00>;
						};

						h2f_usr2_clk {
							clocks = <0x00>;
						};
					};

					mpu_periph_clk {
						clocks = <0x00>;
					};

					mpu_l2_ram_clk {
						clocks = <0x00>;
					};

					l4_main_clk {
						clocks = <0x00>;
					};

					l3_main_clk {
						clocks = <0x00>;
					};

					l3_mp_clk {
						clocks = <0x00>;
					};

					l3_sp_clk {
						clocks = <0x00>;
					};

					l4_mp_clk {
						clocks = <0x00 0x04>;
					};

					l4_sp_clk {
						clocks = <0x00 0x04>;
					};

					dbg_at_clk {
						clocks = <0x00>;
					};

					dbg_clk {
						clocks = <0x00>;
					};

					dbg_trace_clk {
						clocks = <0x00>;
					};

					dbg_timer_clk {
						clocks = <0x00>;
					};

					cfg_clk {
						clocks = <0x00>;
					};

					h2f_user0_clk {
						clocks = <0x00>;
					};

					emac_0_clk {
						clocks = <0x00>;
					};

					emac_1_clk {
						clocks = <0x00>;
					};

					usb_mp_clk {
						clocks = <0x00>;
					};

					spi_m_clk {
						clocks = <0x00>;
					};

					can0_clk {
						clocks = <0x00>;
					};

					can1_clk {
						clocks = <0x00>;
					};

					gpio_db_clk {
						clocks = <0x00>;
					};

					h2f_user1_clk {
						clocks = <0x00>;
					};

					sdmmc_clk {
						clocks = <0x00 0x04 0x08>;
					};

					sdmmc_clk_divided {
						clocks = <0x00>;
					};

					nand_x_clk {
						clocks = <0x00 0x04 0x08>;
					};

					nand_clk {
						clocks = <0x00 0x04 0x08>;
					};

					qspi_clk {
						clocks = <0x00 0x04 0x08>;
					};
				};
			};

			fpga-bridge@ff400000 {
				resets = <0x00>;
				clocks = <0x00>;
			};

			fpga-bridge@ff500000 {
				resets = <0x00>;
				clocks = <0x00>;
			};

			fpga-bridge@ff600000 {
				resets = <0x00>;
				clocks = <0x00>;
			};

			ethernet@ff700000 {
				altr,sysmgr-syscon = <0x00>;
				clocks = <0x00>;
				resets = <0x00>;
			};

			ethernet@ff702000 {
				altr,sysmgr-syscon = <0x00>;
				clocks = <0x00>;
				resets = <0x00>;
			};

			i2c@ffc04000 {
				clocks = <0x00>;

				adxl345@0 {
					interrupt-parent = <0x00>;
				};
			};

			i2c@ffc05000 {
				clocks = <0x00>;
			};

			i2c@ffc06000 {
				clocks = <0x00>;
			};

			i2c@ffc07000 {
				clocks = <0x00>;
			};

			gpio@ff708000 {
				clocks = <0x00>;
			};

			gpio@ff709000 {
				clocks = <0x00>;
			};

			gpio@ff70a000 {
				clocks = <0x00>;
			};

			sdramedac {
				altr,sdr-syscon = <0x00>;
			};

			eccmgr@ffd08140 {

				ocram-ecc@ffd08144 {
					iram = <0x00>;
				};
			};

			dwmmc0@ff704000 {
				clocks = <0x00 0x04>;
				vmmc-supply = <0x00>;
				vqmmc-supply = <0x00>;
			};

			nand@ff900000 {
				clocks = <0x00>;
			};

			spi@ff705000 {
				clocks = <0x00>;
			};

			spi@fff00000 {
				tx-dma-channel = <0x00>;
				rx-dma-channel = <0x00>;
				clocks = <0x00>;
			};

			spi@fff01000 {
				tx-dma-channel = <0x00>;
				rx-dma-channel = <0x00>;
				clocks = <0x00>;
			};

			timer@fffec600 {
				clocks = <0x00>;
			};

			timer0@ffc08000 {
				clocks = <0x00>;
			};

			timer1@ffc09000 {
				clocks = <0x00>;
			};

			timer2@ffd00000 {
				clocks = <0x00>;
			};

			timer3@ffd01000 {
				clocks = <0x00>;
			};

			serial0@ffc02000 {
				clocks = <0x00>;
				dmas = <0x00 0x08>;
			};

			serial1@ffc03000 {
				clocks = <0x00>;
				dmas = <0x00 0x08>;
			};

			usb@ffb00000 {
				clocks = <0x00>;
				phys = <0x00>;
			};

			usb@ffb40000 {
				clocks = <0x00>;
				phys = <0x00>;
			};

			watchdog@ffd02000 {
				clocks = <0x00>;
			};

			watchdog@ffd03000 {
				clocks = <0x00>;
			};
		};

		leds {

			hps0 {
				gpios = <0x00>;
			};
		};

		keys {

			hps0 {
				gpios = <0x00>;
			};
		};
	};
};
